AUTOSAR XML (schema 00046)
standard types defined: float
package /Cluster
  can cluster Cluster0: baudrate=500000
    can physical channel Pch0
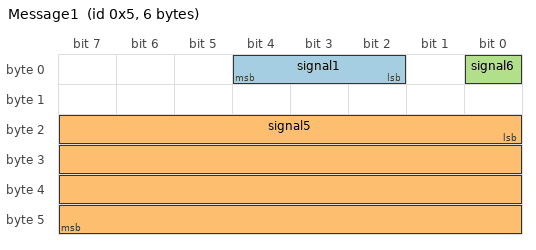
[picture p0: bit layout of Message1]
      frame Message1: id 0x5, frame-length=6, can-addressing-mode=STANDARD  # Comment1 / Kommentar1
        pdu message1: length=6
          signal signal1: start 4, 3 bit, big-endian, system signal Signal1, compu {phys=raw*5 for raw 0..4}, unit=m  # Signal comment! / Signalkommentar!
          signal signal5: start 16, 32 bit, little-endian, base-type=float
          signal signal6: start 0, 1 bit, little-endian, system signal Signal6, compu {0=zero, phys=raw*0.1 for raw 0..1}
          mapping SignalGroup: i-signal-group=todo, transfer-property=PENDING, update-indication-bit-position=4
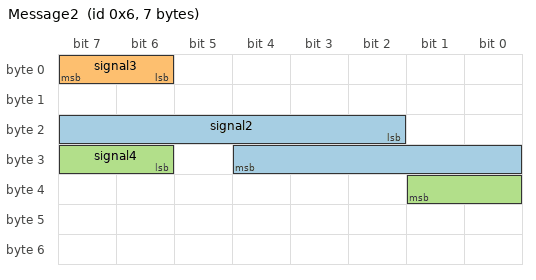
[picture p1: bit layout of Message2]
      frame Message2: id 0x6, frame-length=7, can-addressing-mode=EXTENDED
        pdu message2: length=7, transmission-mode-false-timing=cyclic-timing={time-offset=0, time-period=0.1}, transmission-mode-true-timing=cyclic-timing={time-offset=0, time-period=0.2}
          signal signal2: start 18, 11 bit, little-endian, system signal Signal2, base-type=S16  # Signal comment!
          signal signal3: start 6, 2 bit, little-endian
          signal signal4: start 30, 4 bit, little-endian, system signal Signal4, base-type=U8, compu {0..3, 1=one, 2=two}
      frame Message3: id 0x64, frame-length=8, can-addressing-mode=STANDARD
        pdu message3: length=8
package /Unit
  unit meters: display-name=m
package /SwBaseType
  base type S16: category=FIXED_LENGTH, base-type-size=16, base-type-encoding=2C
  base type U8: category=FIXED_LENGTH, base-type-size=8, base-type-encoding=NONE
